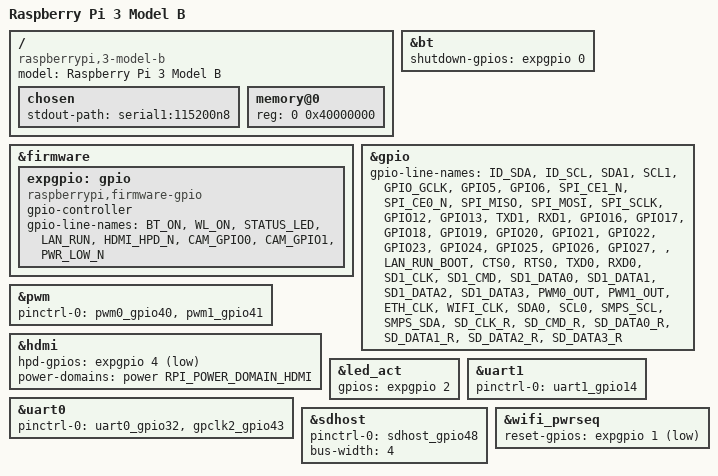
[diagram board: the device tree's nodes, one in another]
/dts-v1/;
#include "bcm2837.dtsi"
#include "bcm2836-rpi.dtsi"
#include "bcm283x-rpi-led-deprecated.dtsi"
#include "bcm283x-rpi-smsc9514.dtsi"
#include "bcm283x-rpi-usb-host.dtsi"
#include "bcm283x-rpi-wifi-bt.dtsi"
/ {
	compatible = "raspberrypi,3-model-b", "brcm,bcm2837";
	model = "Raspberry Pi 3 Model B";
	chosen {
		stdout-path = "serial1:115200n8";
	};
	memory@0 {
		device_type = "memory";
		reg = <0 0x40000000>;
	};
};
&bt {
	shutdown-gpios = <&expgpio 0 GPIO_ACTIVE_HIGH>;
};
&firmware {
	expgpio: gpio {
		compatible = "raspberrypi,firmware-gpio";
		gpio-controller;
		#gpio-cells = <2>;
		gpio-line-names = "BT_ON",
				  "WL_ON",
				  "STATUS_LED",
				  "LAN_RUN",
				  "HDMI_HPD_N",
				  "CAM_GPIO0",
				  "CAM_GPIO1",
				  "PWR_LOW_N";
		status = "okay";
	};
};
&gpio {
	gpio-line-names = "ID_SDA",
			  "ID_SCL",
			  "SDA1",
			  "SCL1",
			  "GPIO_GCLK",
			  "GPIO5",
			  "GPIO6",
			  "SPI_CE1_N",
			  "SPI_CE0_N",
			  "SPI_MISO",
			  "SPI_MOSI",
			  "SPI_SCLK",
			  "GPIO12",
			  "GPIO13",
			  "TXD1",
			  "RXD1",
			  "GPIO16",
			  "GPIO17",
			  "GPIO18",
			  "GPIO19",
			  "GPIO20",
			  "GPIO21",
			  "GPIO22",
			  "GPIO23",
			  "GPIO24",
			  "GPIO25",
			  "GPIO26",
			  "GPIO27",
			  "",  
			  "LAN_RUN_BOOT",
			  "CTS0",
			  "RTS0",
			  "TXD0",
			  "RXD0",
			  "SD1_CLK",
			  "SD1_CMD",
			  "SD1_DATA0",
			  "SD1_DATA1",
			  "SD1_DATA2",
			  "SD1_DATA3",
			  "PWM0_OUT",
			  "PWM1_OUT",
			  "ETH_CLK",
			  "WIFI_CLK",
			  "SDA0",
			  "SCL0",
			  "SMPS_SCL",
			  "SMPS_SDA",
			  "SD_CLK_R",
			  "SD_CMD_R",
			  "SD_DATA0_R",
			  "SD_DATA1_R",
			  "SD_DATA2_R",
			  "SD_DATA3_R";
};
&pwm {
	pinctrl-names = "default";
	pinctrl-0 = <&pwm0_gpio40 &pwm1_gpio41>;
	status = "okay";
};
&hdmi {
	hpd-gpios = <&expgpio 4 GPIO_ACTIVE_LOW>;
	power-domains = <&power RPI_POWER_DOMAIN_HDMI>;
	status = "okay";
};
&led_act {
	gpios = <&expgpio 2 GPIO_ACTIVE_HIGH>;
};
&uart0 {
	pinctrl-names = "default";
	pinctrl-0 = <&uart0_gpio32 &gpclk2_gpio43>;
};
&uart1 {
	pinctrl-names = "default";
	pinctrl-0 = <&uart1_gpio14>;
	status = "okay";
};
&sdhost {
	pinctrl-names = "default";
	pinctrl-0 = <&sdhost_gpio48>;
	status = "okay";
	bus-width = <4>;
};
&wifi_pwrseq {
	reset-gpios = <&expgpio 1 GPIO_ACTIVE_LOW>;
};
